# CSI_TX_IF_V2_0_COMMON_0_CP_INTD_CFG_INTD_CFG register map
Vendor: Texas Instruments
Peripheral module from a debugger description file (folder J7_AHP).
Registers are 32-bit, access not given, reset 0x0 unless marked. A register's access mark holds for its fields unless they carry their own. Offsets are as the file gives them; lines under a group give offsets from that group; [hi:lo] are bit positions; {n}, {i} and the like mark numbered series; 'fields as' and 'values as' point back to an identical list; <NAME> marks a mode.

## CSI_TX_IF_V2_0_COMMON_0_CP_INTD_CFG_INTD_CFG
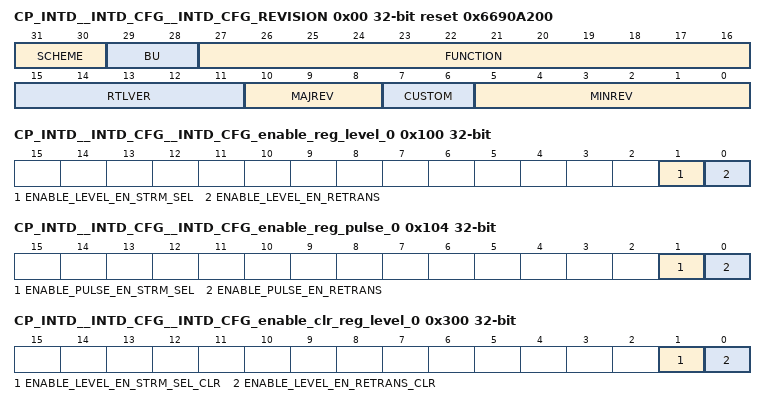
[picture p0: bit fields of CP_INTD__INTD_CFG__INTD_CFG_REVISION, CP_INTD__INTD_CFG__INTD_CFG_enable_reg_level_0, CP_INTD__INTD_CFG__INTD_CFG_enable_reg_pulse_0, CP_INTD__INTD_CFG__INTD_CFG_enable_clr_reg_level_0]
0x00 CP_INTD__INTD_CFG__INTD_CFG_REVISION ro reset 0x6690A200
  [31:30] SCHEME
  [29:28] BU
  [27:16] FUNCTION — Module ID
  [15:11] RTLVER — RTL revisions
  [10:8] MAJREV — Major revision
  [7:6] CUSTOM — Custom revision
  [5:0] MINREV — Minor revision
0x10 CP_INTD__INTD_CFG__INTD_CFG_eoi_reg rw
  [7:0] EOI_VECTOR — End of Interrupt Vector
0x14 CP_INTD__INTD_CFG__INTD_CFG_intr_vector_reg ro
  [31:0] INTR_VECTOR — Interrupt Vector Register
0x100 CP_INTD__INTD_CFG__INTD_CFG_enable_reg_level_0
  [1] ENABLE_LEVEL_EN_STRM_SEL — Enable Set for level_en_strm_sel (access R/W1TS)
  [0] ENABLE_LEVEL_EN_RETRANS — Enable Set for level_en_retrans (access R/W1TS)
0x104 CP_INTD__INTD_CFG__INTD_CFG_enable_reg_pulse_0
  [1] ENABLE_PULSE_EN_STRM_SEL — Enable Set for pulse_en_strm_sel (access R/W1TS)
  [0] ENABLE_PULSE_EN_RETRANS — Enable Set for pulse_en_retrans (access R/W1TS)
0x300 CP_INTD__INTD_CFG__INTD_CFG_enable_clr_reg_level_0
  [1] ENABLE_LEVEL_EN_STRM_SEL_CLR — Enable Clear for level_en_strm_sel (access R/W1TC)
  [0] ENABLE_LEVEL_EN_RETRANS_CLR — Enable Clear for level_en_retrans (access R/W1TC)
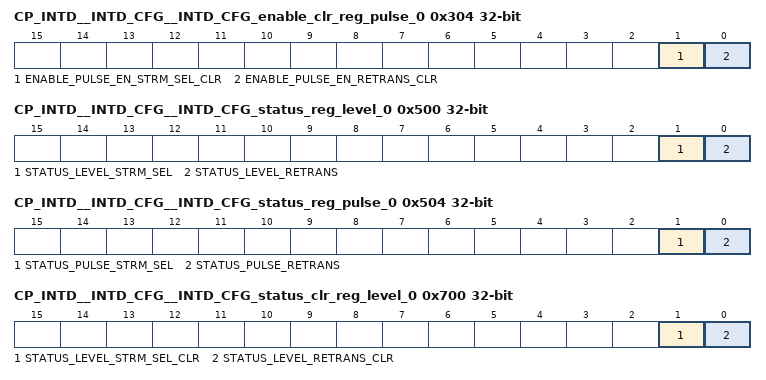
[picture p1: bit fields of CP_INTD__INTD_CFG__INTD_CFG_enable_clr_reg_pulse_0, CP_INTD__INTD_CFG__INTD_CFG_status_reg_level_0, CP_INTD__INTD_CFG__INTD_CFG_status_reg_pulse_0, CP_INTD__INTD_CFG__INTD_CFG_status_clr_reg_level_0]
0x304 CP_INTD__INTD_CFG__INTD_CFG_enable_clr_reg_pulse_0
  [1] ENABLE_PULSE_EN_STRM_SEL_CLR — Enable Clear for pulse_en_strm_sel (access R/W1TC)
  [0] ENABLE_PULSE_EN_RETRANS_CLR — Enable Clear for pulse_en_retrans (access R/W1TC)
0x500 CP_INTD__INTD_CFG__INTD_CFG_status_reg_level_0
  [1] STATUS_LEVEL_STRM_SEL — Status ,write 1 to set, for level_en_strm_sel (access R/W1TS)
  [0] STATUS_LEVEL_RETRANS — Status ,write 1 to set, for level_en_retrans (access R/W1TS)
0x504 CP_INTD__INTD_CFG__INTD_CFG_status_reg_pulse_0
  [1] STATUS_PULSE_STRM_SEL — Status ,write 1 to set, for pulse_en_strm_sel (access R/W1TS)
  [0] STATUS_PULSE_RETRANS — Status ,write 1 to set, for pulse_en_retrans (access R/W1TS)
0x700 CP_INTD__INTD_CFG__INTD_CFG_status_clr_reg_level_0
  [1] STATUS_LEVEL_STRM_SEL_CLR — Status ,write 1 to clear, for level_en_strm_sel (access R/W1TC)
  [0] STATUS_LEVEL_RETRANS_CLR — Status ,write 1 to clear, for level_en_retrans (access R/W1TC)
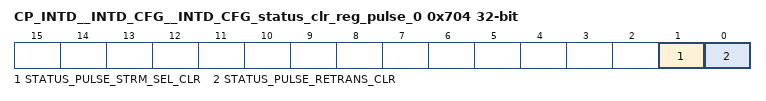
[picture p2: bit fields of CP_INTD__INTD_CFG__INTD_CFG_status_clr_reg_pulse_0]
0x704 CP_INTD__INTD_CFG__INTD_CFG_status_clr_reg_pulse_0
  [1] STATUS_PULSE_STRM_SEL_CLR — Status ,write 1 to clear, for pulse_en_strm_sel (access R/W1TC)
  [0] STATUS_PULSE_RETRANS_CLR — Status ,write 1 to clear, for pulse_en_retrans (access R/W1TC)
0xA80 CP_INTD__INTD_CFG__INTD_CFG_intr_vector_reg_level ro
  [31:0] INTR_VECTOR_LEVEL — Interrupt Vector
0xA84 CP_INTD__INTD_CFG__INTD_CFG_intr_vector_reg_pulse ro
  [31:0] INTR_VECTOR_PULSE — Interrupt Vector
